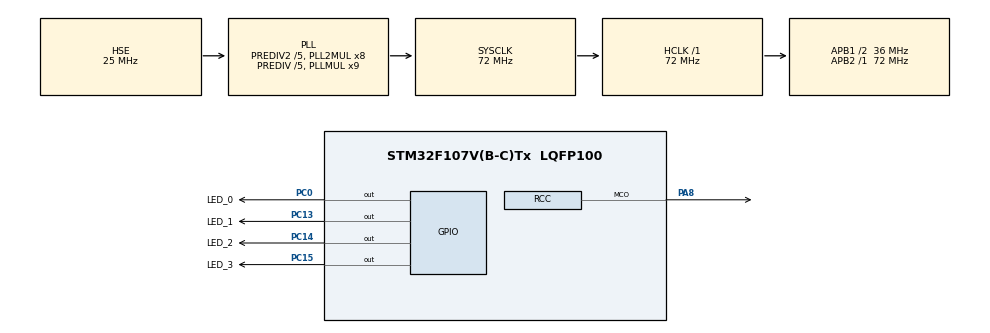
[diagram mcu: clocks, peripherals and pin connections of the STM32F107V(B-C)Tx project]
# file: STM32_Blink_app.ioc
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Mcu.Family=STM32F1
Mcu.Name=STM32F107V(B-C)Tx
Mcu.Package=LQFP100
NVIC.PriorityGroup=NVIC_PRIORITYGROUP_4
OSC_IN.Mode=HSE-External-Oscillator
OSC_IN.Signal=RCC_OSC_IN
OSC_OUT.Mode=HSE-External-Oscillator
OSC_OUT.Signal=RCC_OSC_OUT
PA13.Mode=JTAG_5_pins
PA13.Signal=SYS_JTMS-SWDIO
PA14.Mode=JTAG_5_pins
PA14.Signal=SYS_JTCK-SWCLK
PA15.Mode=JTAG_5_pins
PA15.Signal=SYS_JTDI
PA8.GPIO_Speed=GPIO_SPEED_FREQ_MEDIUM
PA8.Mode=Clock-out
PA8.Signal=RCC_MCO
PB3.Mode=JTAG_5_pins
PB3.Signal=SYS_JTDO
PB4.Mode=JTAG_5_pins
PB4.Signal=SYS_NJTRST
PC0.GPIO_Label=LED_0
PC0.Signal=GPIO_Output
PC13-TAMPER-RTC.GPIO_Label=LED_1
PC13-TAMPER-RTC.Signal=GPIO_Output
PC14-OSC32_IN.GPIO_Label=LED_2
PC14-OSC32_IN.Signal=GPIO_Output
PC15-OSC32_OUT.GPIO_Label=LED_3
PC15-OSC32_OUT.Signal=GPIO_Output
ProjectManager.HeapSize=0x200
ProjectManager.StackSize=0x400
ProjectManager.TargetToolchain=STM32CubeIDE
RCC.AHBFreq_Value=72000000
RCC.APB1CLKDivider=RCC_HCLK_DIV2
RCC.APB1Freq_Value=36000000
RCC.APB1TimFreq_Value=72000000
RCC.APB2Freq_Value=72000000
RCC.APB2TimFreq_Value=72000000
RCC.HCLKFreq_Value=72000000
RCC.HSEDivPLL=RCC_HSE_PREDIV_DIV5
RCC.HSE_VALUE=25000000
RCC.PLL3Mul=RCC_PLLI2S_MUL10
RCC.PLLMUL=RCC_PLL_MUL9
RCC.PLLSourceVirtual=RCC_PLLSOURCE_HSE
RCC.Prediv1Source=RCC_PREDIV1_SOURCE_PLL2
RCC.Prediv2=RCC_HSE_PREDIV2_DIV5
RCC.RCC_MCOSource=RCC_MCO1SOURCE_PLL3CLK
RCC.SYSCLKFreq_VALUE=72000000
RCC.SYSCLKSource=RCC_SYSCLKSOURCE_PLLCLK
RCC.USBFreq_Value=48000000
board=custom

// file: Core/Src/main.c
/* USER CODE BEGIN Header */
/**
  ******************************************************************************
  * @file           : main.c
  * @brief          : Main program body
  ******************************************************************************
  * @attention
  *
  * Copyright (c) 2024 STMicroelectronics.
  * All rights reserved.
  *
  * This software is licensed under terms that can be found in the LICENSE file
  * in the root directory of this software component.
  * If no LICENSE file comes with this software, it is provided AS-IS.
  *
  ******************************************************************************
  */
/* USER CODE END Header */
#include "main.h"

void SystemClock_Config(void);
static void MX_GPIO_Init(void);

int main(void)
{

  /* MCU Configuration--------------------------------------------------------*/

  /* Reset of all peripherals, Initializes the Flash interface and the Systick. */
  HAL_Init();

  /* Configure the system clock */
  SystemClock_Config();

  /* Initialize all configured peripherals */
  MX_GPIO_Init();
  /* USER CODE BEGIN 2 */
  int LED_DELAY = 100;
  /* USER CODE END 2 */

  /* Infinite loop */
  /* USER CODE BEGIN WHILE */
  while (1)
  {
	  HAL_GPIO_TogglePin(GPIOC, LED_1_Pin);
	  HAL_Delay(LED_DELAY);
	  HAL_GPIO_TogglePin(GPIOC, LED_2_Pin);
	  HAL_Delay(LED_DELAY);
	  HAL_GPIO_TogglePin(GPIOC, LED_0_Pin);
	  HAL_Delay(LED_DELAY);
	  HAL_GPIO_TogglePin(GPIOC, LED_3_Pin);
	  HAL_Delay(LED_DELAY);
    /* USER CODE END WHILE */

  }
}

void SystemClock_Config(void)
{
  RCC_OscInitTypeDef RCC_OscInitStruct = {0};
  RCC_ClkInitTypeDef RCC_ClkInitStruct = {0};

  /** Initializes the RCC Oscillators according to the specified parameters
  * in the RCC_OscInitTypeDef structure.
  */
  RCC_OscInitStruct.OscillatorType = RCC_OSCILLATORTYPE_HSE;
  RCC_OscInitStruct.HSEState = RCC_HSE_ON;
  RCC_OscInitStruct.HSEPredivValue = RCC_HSE_PREDIV_DIV5;
  RCC_OscInitStruct.HSIState = RCC_HSI_ON;
  RCC_OscInitStruct.Prediv1Source = RCC_PREDIV1_SOURCE_PLL2;
  RCC_OscInitStruct.PLL.PLLState = RCC_PLL_ON;
  RCC_OscInitStruct.PLL.PLLSource = RCC_PLLSOURCE_HSE;
  RCC_OscInitStruct.PLL.PLLMUL = RCC_PLL_MUL9;
  RCC_OscInitStruct.PLL2.PLL2State = RCC_PLL2_ON;
  RCC_OscInitStruct.PLL2.PLL2MUL = RCC_PLL2_MUL8;
  RCC_OscInitStruct.PLL2.HSEPrediv2Value = RCC_HSE_PREDIV2_DIV5;
  if (HAL_RCC_OscConfig(&RCC_OscInitStruct) != HAL_OK)
  {
    Error_Handler();
  }

  /** Initializes the CPU, AHB and APB buses clocks
  */
  RCC_ClkInitStruct.ClockType = RCC_CLOCKTYPE_HCLK|RCC_CLOCKTYPE_SYSCLK
                              |RCC_CLOCKTYPE_PCLK1|RCC_CLOCKTYPE_PCLK2;
  RCC_ClkInitStruct.SYSCLKSource = RCC_SYSCLKSOURCE_PLLCLK;
  RCC_ClkInitStruct.AHBCLKDivider = RCC_SYSCLK_DIV1;
  RCC_ClkInitStruct.APB1CLKDivider = RCC_HCLK_DIV2;
  RCC_ClkInitStruct.APB2CLKDivider = RCC_HCLK_DIV1;

  if (HAL_RCC_ClockConfig(&RCC_ClkInitStruct, FLASH_LATENCY_2) != HAL_OK)
  {
    Error_Handler();
  }
  HAL_RCC_MCOConfig(RCC_MCO, RCC_MCO1SOURCE_PLL3CLK, RCC_MCODIV_1);

  /** Configure the Systick interrupt time
  */
  __HAL_RCC_HSE_PREDIV2_CONFIG(RCC_HSE_PREDIV2_DIV5);

  /** Configure the Systick interrupt time
  */
  __HAL_RCC_PLLI2S_CONFIG(RCC_PLLI2S_MUL10);

  /** Configure the Systick interrupt time
  */
  __HAL_RCC_PLLI2S_ENABLE();
}

static void MX_GPIO_Init(void)
{
  GPIO_InitTypeDef GPIO_InitStruct = {0};

  /* GPIO Ports Clock Enable */
  __HAL_RCC_GPIOC_CLK_ENABLE();
  __HAL_RCC_GPIOA_CLK_ENABLE();
  __HAL_RCC_GPIOB_CLK_ENABLE();

  /*Configure GPIO pin Output Level */
  HAL_GPIO_WritePin(GPIOC, LED_1_Pin|LED_2_Pin|LED_3_Pin|LED_0_Pin, GPIO_PIN_RESET);

  /*Configure GPIO pins : LED_1_Pin LED_2_Pin LED_3_Pin LED_0_Pin */
  GPIO_InitStruct.Pin = LED_1_Pin|LED_2_Pin|LED_3_Pin|LED_0_Pin;
  GPIO_InitStruct.Mode = GPIO_MODE_OUTPUT_PP;
  GPIO_InitStruct.Pull = GPIO_NOPULL;
  GPIO_InitStruct.Speed = GPIO_SPEED_FREQ_LOW;
  HAL_GPIO_Init(GPIOC, &GPIO_InitStruct);

  /*Configure GPIO pin : PA8 */
  GPIO_InitStruct.Pin = GPIO_PIN_8;
  GPIO_InitStruct.Mode = GPIO_MODE_AF_PP;
  GPIO_InitStruct.Speed = GPIO_SPEED_FREQ_MEDIUM;
  HAL_GPIO_Init(GPIOA, &GPIO_InitStruct);

}

void Error_Handler(void)
{
  __disable_irq();
  while (1)
  {
  }
}
